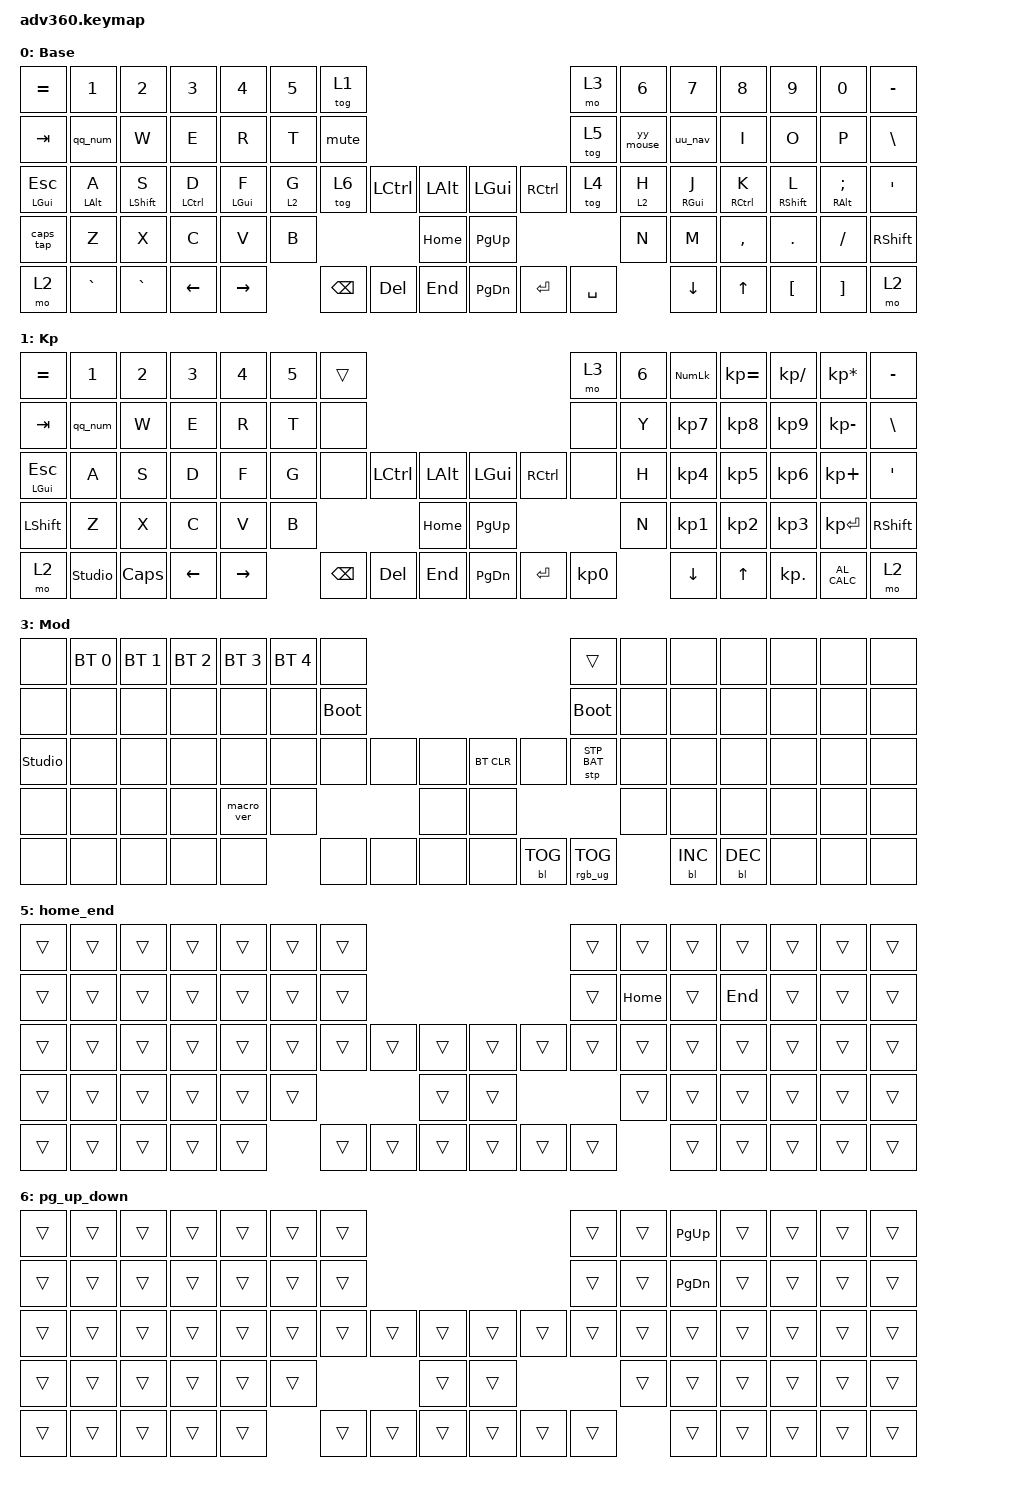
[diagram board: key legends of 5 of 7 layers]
#include <dt-bindings/zmk/stp.h>
#include <behaviors.dtsi>
#include <dt-bindings/zmk/backlight.h>
#include <dt-bindings/zmk/bt.h>
#include <dt-bindings/zmk/keys.h>
#include <dt-bindings/zmk/pointing.h>
#include <dt-bindings/zmk/rgb.h>

/ {
    behaviors {
        #include "macros.dtsi"
      #include "version.dtsi"

        hm: homerow_mods {
            compatible = "zmk,behavior-hold-tap";
            label = "HOMEROW_MODS";
            #binding-cells = <2>;
            tapping-term-ms = <280>;
            flavor = "balanced";
            bindings = <&kp>, <&kp>;

            quick-tap-ms = <175>;
            require-prior-idle-ms = <150>;
        };

        esc_win: esc_win {
            compatible = "zmk,behavior-hold-tap";
            label = "ESC_WIN";
            bindings = <&kp>, <&kp>;

            #binding-cells = <2>;
            tapping-term-ms = <150>;
        };

        hm2: hm2 {
            compatible = "zmk,behavior-hold-tap";
            label = "HM2";
            #binding-cells = <2>;
            tapping-term-ms = <280>;
            flavor = "balanced";
            quick-tap-ms = <175>;
            require-prior-idle-ms = <150>;
            bindings = <&mo>, <&kp>;
        };

        yy_mouse: yy_mouse {
            compatible = "zmk,behavior-tap-dance";
            label = "YY_MOUSE";
            #binding-cells = <0>;
            tapping-term-ms = <200>;
            bindings = <&kp Y>, <&tog 5>;
        };

        uu_nav: uu_nav {
            compatible = "zmk,behavior-tap-dance";
            label = "UU_NAV";
            #binding-cells = <0>;
            tapping-term-ms = <200>;
            bindings = <&kp U>, <&tog 4>;
        };

        qq_num: qq_num {
            compatible = "zmk,behavior-tap-dance";
            label = "QQ_NUM";
            #binding-cells = <0>;
            tapping-term-ms = <200>;
            bindings = <&kp Q>, <&tog 1>;
        };

        caps_tap: caps_tap {
            compatible = "zmk,behavior-tap-dance";
            label = "CAPS_TAP";
            #binding-cells = <0>;
            tapping-term-ms = <200>;
            bindings = <&kp LEFT_SHIFT>, <&kp CAPSLOCK>;
        };
    };

    macros {
        mute: mute {
            compatible = "zmk,behavior-macro";
            #binding-cells = <0>;
            bindings = <&kp LA(A) &kp LC(D)>;
            label = "MUTE";
        };

        email: email {
            compatible = "zmk,behavior-macro";
            #binding-cells = <0>;
            bindings = <&kp K &kp B &kp A &kp L &kp K &kp O &kp S &kp K &kp I &kp AT &kp G &kp M &kp A &kp I &kp L &kp DOT &kp C &kp O &kp M>;
            label = "EMAIL";
        };

        email_work: email_work {
            compatible = "zmk,behavior-macro";
            #binding-cells = <0>;
            bindings = <&kp K &kp E &kp V &kp I &kp N &kp AT &kp N &kp O &kp C &kp K &kp L &kp O &kp DOT &kp C &kp O &kp M>;
            label = "EMAIL_WORK";
        };

        trip_tick: trip_tick {
            compatible = "zmk,behavior-macro";
            #binding-cells = <0>;
            bindings = <&kp GRAVE &kp GRAVE &kp GRAVE>;
            label = "TRIP_TICK";
        };
    };

    combos { compatible = "zmk,combos"; };

    keymap {
        compatible = "zmk,keymap";

        default_layer {
            display-name = "Base";
            bindings = <
&kp EQUAL          &kp N1      &kp N2            &kp N3       &kp N4          &kp N5    &tog 1                                                   &mo 3      &kp N6     &kp N7           &kp N8        &kp N9             &kp N0              &kp MINUS
&kp TAB            &qq_num     &kp W             &kp E        &kp R           &kp T     &mute                                                    &tog 5     &yy_mouse  &uu_nav          &kp I         &kp O              &kp P               &kp BSLH
&esc_win LGUI ESC  &hm LALT A  &hm LEFT_SHIFT S  &hm LCTRL D  &hm LEFT_GUI F  &hm2 2 G  &tog 6    &kp LCTRL  &kp LALT      &kp LGUI   &kp RCTRL  &tog 4     &hm2 2 H   &hm RIGHT_GUI J  &hm RCTRL K   &hm RIGHT_SHIFT L  &hm RIGHT_ALT SEMI  &kp SQT
&caps_tap          &kp Z       &kp X             &kp C        &kp V           &kp B                          &kp HOME      &kp PG_UP                        &kp N      &kp M            &kp COMMA     &kp DOT            &kp FSLH            &kp RSHFT
&mo 2              &kp GRAVE   &kp GRAVE         &kp LEFT     &kp RIGHT                 &kp BSPC  &kp DEL    &kp END       &kp PG_DN  &kp ENTER  &kp SPACE             &kp DOWN_ARROW   &kp UP_ARROW  &kp LBKT           &kp RBKT            &mo 2
            >;
        };

        keypad {
            display-name = "Kp";
            bindings = <
&kp EQUAL                 &kp N1          &kp N2    &kp N3    &kp N4     &kp N5  &trans                                                   &mo 3      &kp N6  &kp KP_NUM      &kp KP_EQUAL  &kp KP_DIVIDE  &kp KP_MULTIPLY  &kp MINUS
&kp TAB                   &qq_num         &kp W     &kp E     &kp R      &kp T   &none                                                    &none      &kp Y   &kp KP_N7       &kp KP_N8     &kp KP_N9      &kp KP_MINUS     &kp BSLH
&esc_win LEFT_GUI ESCAPE  &kp A           &kp S     &kp D     &kp F      &kp G   &none     &kp LCTRL  &kp LALT      &kp LGUI   &kp RCTRL  &none      &kp H   &kp KP_N4       &kp KP_N5     &kp KP_N6      &kp KP_PLUS      &kp SQT
&kp LSHFT                 &kp Z           &kp X     &kp C     &kp V      &kp B                        &kp HOME      &kp PG_UP                        &kp N   &kp KP_N1       &kp KP_N2     &kp KP_N3      &kp KP_ENTER     &kp RSHFT
&mo 2                     &studio_unlock  &kp CAPS  &kp LEFT  &kp RIGHT          &kp BSPC  &kp DEL    &kp END       &kp PG_DN  &kp ENTER  &kp KP_N0          &kp DOWN_ARROW  &kp UP_ARROW  &kp KP_DOT     &kp C_AL_CALC    &mo 2
            >;
        };

        fn {
            display-name = "Fn";
            bindings = <
&kp F1  &kp F2      &kp F3                    &kp F4                     &kp F5         &kp F6         &tog 1                                                                   &mo 3   &kp F7          &kp F8              &kp F9              &kp F10          &kp F11             &kp F12
&trans  &trans      &kp LEFT_BRACE            &kp LEFT_BRACKET           &kp LG(LC(R))  &kp LA(LC(T))  &none                                                                    &none   &email          &trans              &kp RIGHT_BRACKET   &kp RIGHT_BRACE  &trans              &trans
&trans  &trans      &kp LS(LC(LEFT_BRACKET))  &kp LS(LC(RIGHT_BRACKET))  &kp LC(LA(F))  &trans         &none                 &trans  &trans      &trans  &trans                 &none   &kp LEFT_ARROW  &kp DOWN_ARROW      &kp UP_ARROW        &kp RIGHT_ARROW  &trans              &trip_tick
&trans  &trans      &trans                    &trans                     &kp LA(LC(V))  &trans                                       &trans      &trans                                 &trans          &trans              &kp C_VOL_DN        &kp C_VOLUME_UP  &kp LA(LS(LC(F1)))  &trans
&trans  &trip_tick  &trip_tick                &trans                     &trans                        &kp LC(LEFT_BRACKET)  &trans  &trans      &trans  &kp LC(LS(LA(ENTER)))  &trans                  &kp LA(LC(LS(F3)))  &kp LS(LA(LC(F2)))  &trans           &trans              &trans
            >;
        };

        mod {
            display-name = "Mod";
            bindings = <
&none           &bt BT_SEL 0  &bt BT_SEL 1  &bt BT_SEL 2  &bt BT_SEL 3  &bt BT_SEL 4  &none                                                  &trans           &none  &none       &none       &none  &none  &none
&none           &none         &none         &none         &none         &none         &bootloader                                            &bootloader      &none  &none       &none       &none  &none  &none
&studio_unlock  &none         &none         &none         &none         &none         &none        &none  &none      &bt BT_CLR  &none       &stp STP_BAT     &none  &none       &none       &none  &none  &none
&none           &none         &none         &none         &macro_ver    &none                             &none      &none                                    &none  &none       &none       &none  &none  &none
&none           &none         &none         &none         &none                       &none        &none  &none      &none       &bl BL_TOG  &rgb_ug RGB_TOG         &bl BL_INC  &bl BL_DEC  &none  &none  &none
            >;
        };

        extra1 {
            display-name = "Red";
            status = "reserved";
            bindings = <
&trans  &trans  &trans  &trans  &trans  &trans  &trans                                      &trans  &trans        &trans         &trans         &trans  &trans  &trans
&trans  &trans  &trans  &trans  &trans  &trans  &trans                                      &trans  &trans        &uu_nav        &trans         &trans  &trans  &trans
&trans  &trans  &trans  &trans  &trans  &trans  &trans  &trans  &trans      &trans  &trans  &trans  &kp HOME      &kp END        &kp PAGE_DOWN  &trans  &trans  &trans
&trans  &trans  &trans  &trans  &trans  &trans                  &trans      &trans                  &kp LC(LEFT)  &kp LC(RIGHT)  &trans         &trans  &trans  &trans
&trans  &trans  &trans  &trans  &trans          &trans  &trans  &trans      &trans  &trans  &trans                &trans         &trans         &trans  &trans  &trans
            >;
        };

        mouse {
            display-name = "Purple";
            bindings = <
&trans  &kp LG(NUMBER_1)   &kp LG(NUMBER_2)          &kp LG(NUMBER_3)  &kp LG(NUMBER_4)           &kp LG(N5)        &trans                                      &trans  &kp LG(NUMBER_6)  &kp LG(N7)        &kp LG(N8)        &kp LG(N9)  &trans  &trans
&trans  &trans             &kp LS(LC(LEFT_BRACKET))  &mmv MOVE_UP      &kp LS(LC(RIGHT_BRACKET))  &trans            &trans                                      &trans  &yy_mouse         &mkp MB4          &mkp MB5          &trans      &trans  &trans
&trans  &mmv MOVE_X(-600)  &mmv MOVE_LEFT            &mmv MOVE_DOWN    &mmv MOVE_RIGHT            &mmv MOVE_X(600)  &trans  &trans  &trans      &trans  &trans  &trans  &msc MOVE_Y(20)   &mkp LCLK         &mkp RCLK         &trans      &trans  &trans
&trans  &kp LC(Z)          &kp LC(X)                 &kp LC(C)         &kp LC(V)                  &trans                            &trans      &trans                  &msc MOVE_Y(-20)  &msc MOVE_X(-20)  &msc MOVE_X(20)   &trans      &trans  &trans
&trans  &trans             &trans                    &kp LG(LEFT)      &kp LG(RIGHT)                                &trans  &trans  &trans      &trans  &trans  &trans                    &kp LG(DOWN)      &kp LG(UP_ARROW)  &trans
            >;
        };

        extra3 {
            display-name = "Cyan";
            status = "reserved";
            bindings = <
&kp F1             &kp F2      &kp F3            &kp F4       &kp F5          &kp F6    &tog 1                                                   &mo 3      &kp F7    &kp F8           &kp F9        &kp F10            &kp F11             &kp F12
&kp TAB            &kp Q       &kp W             &kp E        &kp R           &kp T     &mute                                                    &tog 5     &kp Y     &kp U            &kp I         &kp O              &kp P               &kp BSLH
&esc_win LGUI ESC  &hm LALT A  &hm LEFT_SHIFT S  &hm LCTRL D  &hm LEFT_GUI F  &hm2 2 G  &tog 6    &kp LCTRL  &kp LALT      &kp LGUI   &kp RCTRL  &tog 8     &hm2 2 H  &hm RIGHT_GUI J  &hm RCTRL K   &hm RIGHT_SHIFT L  &hm RIGHT_ALT SEMI  &kp SQT
&kp LSHFT          &kp Z       &kp X             &kp C        &kp V           &kp B                          &kp HOME      &kp PG_UP                        &kp N     &kp M            &kp COMMA     &kp DOT            &kp FSLH            &kp RSHFT
&mo 2              &kp GRAVE   &kp GRAVE         &kp LEFT     &kp RIGHT                 &kp BSPC  &kp DEL    &kp END       &kp PG_DN  &kp ENTER  &kp SPACE            &kp DOWN_ARROW   &kp UP_ARROW  &kp LBKT           &kp RBKT            &mo 2
            >;
        };

        extra4 {
            display-name = "Yellow";
            status = "reserved";
        };

        home_end {
            bindings = <
&trans  &trans  &trans  &trans  &trans  &trans  &trans                                      &trans  &trans    &trans  &trans   &trans  &trans  &trans
&trans  &trans  &trans  &trans  &trans  &trans  &trans                                      &trans  &kp HOME  &trans  &kp END  &trans  &trans  &trans
&trans  &trans  &trans  &trans  &trans  &trans  &trans  &trans  &trans      &trans  &trans  &trans  &trans    &trans  &trans   &trans  &trans  &trans
&trans  &trans  &trans  &trans  &trans  &trans                  &trans      &trans                  &trans    &trans  &trans   &trans  &trans  &trans
&trans  &trans  &trans  &trans  &trans          &trans  &trans  &trans      &trans  &trans  &trans            &trans  &trans   &trans  &trans  &trans
            >;
        };

        pg_up_down {
            bindings = <
&trans  &trans  &trans  &trans  &trans  &trans  &trans                                      &trans  &trans  &kp PG_UP      &trans  &trans  &trans  &trans
&trans  &trans  &trans  &trans  &trans  &trans  &trans                                      &trans  &trans  &kp PAGE_DOWN  &trans  &trans  &trans  &trans
&trans  &trans  &trans  &trans  &trans  &trans  &trans  &trans  &trans      &trans  &trans  &trans  &trans  &trans         &trans  &trans  &trans  &trans
&trans  &trans  &trans  &trans  &trans  &trans                  &trans      &trans                  &trans  &trans         &trans  &trans  &trans  &trans
&trans  &trans  &trans  &trans  &trans          &trans  &trans  &trans      &trans  &trans  &trans          &trans         &trans  &trans  &trans  &trans
            >;
        };
    };
};
